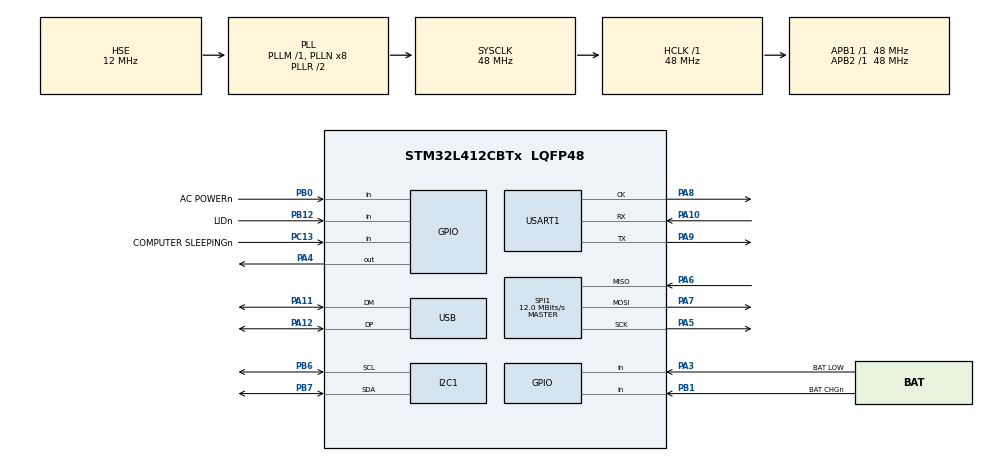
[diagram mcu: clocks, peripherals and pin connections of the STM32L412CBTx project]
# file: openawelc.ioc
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I2C1.Timing=0x10805D88
Mcu.Family=STM32L4
Mcu.Name=STM32L412CBTx
Mcu.Package=LQFP48
NVIC.PriorityGroup=NVIC_PRIORITYGROUP_4
NVIC.USB_IRQn=true\:0\:0\:false\:false\:true\:false\:true\:true
PA10.Mode=Synchronous
PA10.Signal=USART1_RX
PA11.Mode=Device
PA11.Signal=USB_DM
PA12.Mode=Device
PA12.Signal=USB_DP
PA3.GPIO_Label=BAT LOW
PA3.Signal=GPIO_Input
PA4.Signal=GPIO_Output
PA5.Mode=Full_Duplex_Master
PA5.Signal=SPI1_SCK
PA6.Mode=Full_Duplex_Master
PA6.Signal=SPI1_MISO
PA7.Mode=Full_Duplex_Master
PA7.Signal=SPI1_MOSI
PA8.Mode=Synchronous
PA8.Signal=USART1_CK
PA9.Mode=Synchronous
PA9.Signal=USART1_TX
PB0.GPIO_Label=AC POWERn
PB0.Signal=GPIO_Input
PB1.GPIO_Label=BAT CHGn
PB1.Signal=GPIO_Input
PB12.GPIO_Label=LIDn
PB12.Signal=GPIO_Input
PB6.Mode=I2C
PB6.Signal=I2C1_SCL
PB7.Mode=I2C
PB7.Signal=I2C1_SDA
PC13.GPIO_Label=COMPUTER SLEEPINGn
PC13.Signal=GPIO_Input
PH0-OSC_IN\ (PH0).Mode=HSE-External-Oscillator
PH0-OSC_IN\ (PH0).Signal=RCC_OSC_IN
PH1-OSC_OUT\ (PH1).Mode=HSE-External-Oscillator
PH1-OSC_OUT\ (PH1).Signal=RCC_OSC_OUT
ProjectManager.HeapSize=0x200
ProjectManager.StackSize=0x400
ProjectManager.TargetToolchain=STM32CubeIDE
RCC.ADCFreq_Value=48000000
RCC.AHBFreq_Value=48000000
RCC.APB1Freq_Value=48000000
RCC.APB1TimFreq_Value=48000000
RCC.APB2Freq_Value=48000000
RCC.APB2TimFreq_Value=48000000
RCC.CK48CLockSelection=RCC_USBCLKSOURCE_PLL
RCC.CortexFreq_Value=48000000
RCC.HCLKFreq_Value=48000000
RCC.HSE_VALUE=12000000
RCC.HSI48_VALUE=48000000
RCC.HSI_VALUE=16000000
RCC.LSE_VALUE=32768
RCC.MSI_VALUE=4000000
RCC.PLLSourceVirtual=RCC_PLLSOURCE_HSE
RCC.SYSCLKFreq_VALUE=48000000
RCC.SYSCLKSource=RCC_SYSCLKSOURCE_PLLCLK
RCC.USBFreq_Value=48000000
RCC.VCOOutputFreq_Value=96000000
SPI1.BaudRatePrescaler=SPI_BAUDRATEPRESCALER_4
SPI1.CalculateBaudRate=12.0 MBits/s
SPI1.DataSize=SPI_DATASIZE_8BIT
SPI1.Direction=SPI_DIRECTION_2LINES
SPI1.Mode=SPI_MODE_MASTER
SPI1.NSSPMode=SPI_NSS_PULSE_DISABLE
SPI1.VirtualType=VM_MASTER
USART1.VirtualMode-Synchronous=VM_SYNC
USB_DEVICE.CLASS_NAME_FS=CDC
USB_DEVICE.VirtualMode=Cdc
USB_DEVICE.VirtualModeFS=Cdc_FS
VP_USB_DEVICE_VS_USB_DEVICE_CDC_FS.Mode=CDC_FS
board=custom

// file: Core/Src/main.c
/* USER CODE BEGIN Header */
/**
  ******************************************************************************
  * @file           : main.c
  * @brief          : Main program body
  ******************************************************************************
  * @attention
  *
  * Copyright (c) 2025 STMicroelectronics.
  * All rights reserved.
  *
  * This software is licensed under terms that can be found in the LICENSE file
  * in the root directory of this software component.
  * If no LICENSE file comes with this software, it is provided AS-IS.
  *
  ******************************************************************************
  */
/* USER CODE END Header */
#include "main.h"
#include "usb_device.h"
#include "usbd_cdc_if.h"

I2C_HandleTypeDef hi2c1;

SPI_HandleTypeDef hspi1;

USART_HandleTypeDef husart1;

void SystemClock_Config(void);
static void MX_GPIO_Init(void);
static void MX_USART1_Init(void);
static void MX_SPI1_Init(void);
static void MX_I2C1_Init(void);
/* USER CODE BEGIN PFP */
void openawelc_setup(void);
void openawelc_loop(void);
/* USER CODE END PFP */

int main(void)
{

  /* MCU Configuration--------------------------------------------------------*/

  /* Reset of all peripherals, Initializes the Flash interface and the Systick. */
  HAL_Init();

  /* Configure the system clock */
  SystemClock_Config();

  /* Initialize all configured peripherals */
  MX_GPIO_Init();
  MX_USB_DEVICE_Init();
  MX_USART1_Init();
  MX_SPI1_Init();
  MX_I2C1_Init();
  /* USER CODE BEGIN 2 */
  openawelc_setup();
  /* USER CODE END 2 */

  /* Infinite loop */
  /* USER CODE BEGIN WHILE */
  while (1)
  {
	  openawelc_loop();
    /* USER CODE END WHILE */

  }
}

void SystemClock_Config(void)
{
  RCC_OscInitTypeDef RCC_OscInitStruct = {0};
  RCC_ClkInitTypeDef RCC_ClkInitStruct = {0};

  /** Configure the main internal regulator output voltage
  */
  if (HAL_PWREx_ControlVoltageScaling(PWR_REGULATOR_VOLTAGE_SCALE1) != HAL_OK)
  {
    Error_Handler();
  }

  /** Initializes the RCC Oscillators according to the specified parameters
  * in the RCC_OscInitTypeDef structure.
  */
  RCC_OscInitStruct.OscillatorType = RCC_OSCILLATORTYPE_HSE;
  RCC_OscInitStruct.HSEState = RCC_HSE_ON;
  RCC_OscInitStruct.PLL.PLLState = RCC_PLL_ON;
  RCC_OscInitStruct.PLL.PLLSource = RCC_PLLSOURCE_HSE;
  RCC_OscInitStruct.PLL.PLLM = 1;
  RCC_OscInitStruct.PLL.PLLN = 8;
  RCC_OscInitStruct.PLL.PLLQ = RCC_PLLQ_DIV2;
  RCC_OscInitStruct.PLL.PLLR = RCC_PLLR_DIV2;
  if (HAL_RCC_OscConfig(&RCC_OscInitStruct) != HAL_OK)
  {
    Error_Handler();
  }

  /** Initializes the CPU, AHB and APB buses clocks
  */
  RCC_ClkInitStruct.ClockType = RCC_CLOCKTYPE_HCLK|RCC_CLOCKTYPE_SYSCLK
                              |RCC_CLOCKTYPE_PCLK1|RCC_CLOCKTYPE_PCLK2;
  RCC_ClkInitStruct.SYSCLKSource = RCC_SYSCLKSOURCE_PLLCLK;
  RCC_ClkInitStruct.AHBCLKDivider = RCC_SYSCLK_DIV1;
  RCC_ClkInitStruct.APB1CLKDivider = RCC_HCLK_DIV1;
  RCC_ClkInitStruct.APB2CLKDivider = RCC_HCLK_DIV1;

  if (HAL_RCC_ClockConfig(&RCC_ClkInitStruct, FLASH_LATENCY_2) != HAL_OK)
  {
    Error_Handler();
  }
}

static void MX_I2C1_Init(void)
{

  hi2c1.Instance = I2C1;
  hi2c1.Init.Timing = 0x10805D88;
  hi2c1.Init.OwnAddress1 = 0;
  hi2c1.Init.AddressingMode = I2C_ADDRESSINGMODE_7BIT;
  hi2c1.Init.DualAddressMode = I2C_DUALADDRESS_DISABLE;
  hi2c1.Init.OwnAddress2 = 0;
  hi2c1.Init.OwnAddress2Masks = I2C_OA2_NOMASK;
  hi2c1.Init.GeneralCallMode = I2C_GENERALCALL_DISABLE;
  hi2c1.Init.NoStretchMode = I2C_NOSTRETCH_DISABLE;
  if (HAL_I2C_Init(&hi2c1) != HAL_OK)
  {
    Error_Handler();
  }

  /** Configure Analogue filter
  */
  if (HAL_I2CEx_ConfigAnalogFilter(&hi2c1, I2C_ANALOGFILTER_ENABLE) != HAL_OK)
  {
    Error_Handler();
  }

  /** Configure Digital filter
  */
  if (HAL_I2CEx_ConfigDigitalFilter(&hi2c1, 0) != HAL_OK)
  {
    Error_Handler();
  }

}

static void MX_SPI1_Init(void)
{

  /* SPI1 parameter configuration*/
  hspi1.Instance = SPI1;
  hspi1.Init.Mode = SPI_MODE_MASTER;
  hspi1.Init.Direction = SPI_DIRECTION_2LINES;
  hspi1.Init.DataSize = SPI_DATASIZE_8BIT;
  hspi1.Init.CLKPolarity = SPI_POLARITY_LOW;
  hspi1.Init.CLKPhase = SPI_PHASE_1EDGE;
  hspi1.Init.NSS = SPI_NSS_SOFT;
  hspi1.Init.BaudRatePrescaler = SPI_BAUDRATEPRESCALER_4;
  hspi1.Init.FirstBit = SPI_FIRSTBIT_MSB;
  hspi1.Init.TIMode = SPI_TIMODE_DISABLE;
  hspi1.Init.CRCCalculation = SPI_CRCCALCULATION_DISABLE;
  hspi1.Init.CRCPolynomial = 7;
  hspi1.Init.CRCLength = SPI_CRC_LENGTH_DATASIZE;
  hspi1.Init.NSSPMode = SPI_NSS_PULSE_DISABLE;
  if (HAL_SPI_Init(&hspi1) != HAL_OK)
  {
    Error_Handler();
  }

}

static void MX_USART1_Init(void)
{

  husart1.Instance = USART1;
  husart1.Init.BaudRate = 115200;
  husart1.Init.WordLength = USART_WORDLENGTH_8B;
  husart1.Init.StopBits = USART_STOPBITS_1;
  husart1.Init.Parity = USART_PARITY_NONE;
  husart1.Init.Mode = USART_MODE_TX_RX;
  husart1.Init.CLKPolarity = USART_POLARITY_LOW;
  husart1.Init.CLKPhase = USART_PHASE_1EDGE;
  husart1.Init.CLKLastBit = USART_LASTBIT_DISABLE;
  if (HAL_USART_Init(&husart1) != HAL_OK)
  {
    Error_Handler();
  }

}

static void MX_GPIO_Init(void)
{
  GPIO_InitTypeDef GPIO_InitStruct = {0};

  /* GPIO Ports Clock Enable */
  __HAL_RCC_GPIOC_CLK_ENABLE();
  __HAL_RCC_GPIOH_CLK_ENABLE();
  __HAL_RCC_GPIOA_CLK_ENABLE();
  __HAL_RCC_GPIOB_CLK_ENABLE();

  /*Configure GPIO pin Output Level */
  HAL_GPIO_WritePin(GPIOA, GPIO_PIN_4, GPIO_PIN_RESET);

  /*Configure GPIO pin : COMPUTER_SLEEPINGn_Pin */
  GPIO_InitStruct.Pin = COMPUTER_SLEEPINGn_Pin;
  GPIO_InitStruct.Mode = GPIO_MODE_INPUT;
  GPIO_InitStruct.Pull = GPIO_NOPULL;
  HAL_GPIO_Init(COMPUTER_SLEEPINGn_GPIO_Port, &GPIO_InitStruct);

  /*Configure GPIO pin : BAT_LOW_Pin */
  GPIO_InitStruct.Pin = BAT_LOW_Pin;
  GPIO_InitStruct.Mode = GPIO_MODE_INPUT;
  GPIO_InitStruct.Pull = GPIO_NOPULL;
  HAL_GPIO_Init(BAT_LOW_GPIO_Port, &GPIO_InitStruct);

  /*Configure GPIO pin : PA4 */
  GPIO_InitStruct.Pin = GPIO_PIN_4;
  GPIO_InitStruct.Mode = GPIO_MODE_OUTPUT_PP;
  GPIO_InitStruct.Pull = GPIO_NOPULL;
  GPIO_InitStruct.Speed = GPIO_SPEED_FREQ_LOW;
  HAL_GPIO_Init(GPIOA, &GPIO_InitStruct);

  /*Configure GPIO pins : AC_POWERn_Pin BAT_CHGn_Pin LIDn_Pin */
  GPIO_InitStruct.Pin = AC_POWERn_Pin|BAT_CHGn_Pin|LIDn_Pin;
  GPIO_InitStruct.Mode = GPIO_MODE_INPUT;
  GPIO_InitStruct.Pull = GPIO_NOPULL;
  HAL_GPIO_Init(GPIOB, &GPIO_InitStruct);

}

/* USER CODE BEGIN 4 */

// https://github.com/alexeykosinov/Redirect-printf-to-USB-VCP-on-STM32H7-MCU
int _write(int file, char *ptr, int len) {
    static uint8_t rc = USBD_OK;

    do {
        rc = CDC_Transmit_FS((uint8_t*)ptr, len);
    } while (USBD_BUSY == rc);

    if (USBD_FAIL == rc) {
    	Error_Handler();
        return 0;
    }
    return len;
}

/* USER CODE END 4 */

void Error_Handler(void)
{
  __disable_irq();
  while (1)
  {
  }
}
